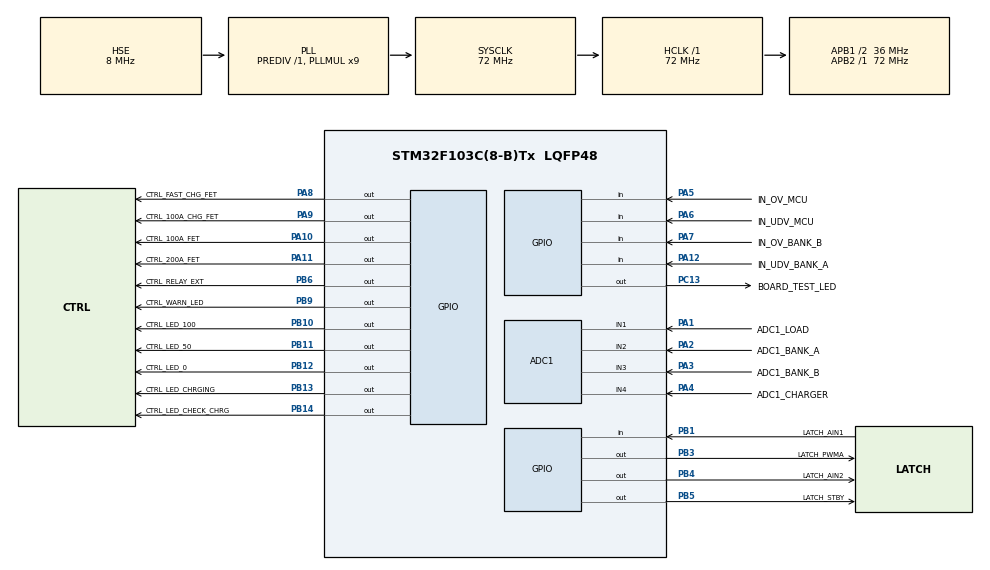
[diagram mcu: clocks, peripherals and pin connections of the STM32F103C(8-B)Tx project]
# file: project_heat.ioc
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ADC1.Channel-0\#ChannelRegularConversion=ADC_CHANNEL_1
ADC1.Channel-1\#ChannelRegularConversion=ADC_CHANNEL_2
ADC1.Channel-2\#ChannelRegularConversion=ADC_CHANNEL_3
ADC1.Channel-3\#ChannelRegularConversion=ADC_CHANNEL_4
ADC1.NbrOfConversion=4
ADC1.NbrOfConversionFlag=1
ADC1.Rank-0\#ChannelRegularConversion=1
ADC1.Rank-1\#ChannelRegularConversion=2
ADC1.Rank-2\#ChannelRegularConversion=3
ADC1.Rank-3\#ChannelRegularConversion=4
ADC1.SamplingTime-0\#ChannelRegularConversion=ADC_SAMPLETIME_239CYCLES_5
ADC1.SamplingTime-1\#ChannelRegularConversion=ADC_SAMPLETIME_239CYCLES_5
ADC1.SamplingTime-2\#ChannelRegularConversion=ADC_SAMPLETIME_1CYCLE_5
ADC1.SamplingTime-3\#ChannelRegularConversion=ADC_SAMPLETIME_239CYCLES_5
ADC1.master=1
Dma.ADC1.0.Direction=DMA_PERIPH_TO_MEMORY
Dma.ADC1.0.Instance=DMA1_Channel1
Dma.ADC1.0.MemDataAlignment=DMA_MDATAALIGN_HALFWORD
Dma.ADC1.0.MemInc=DMA_MINC_ENABLE
Dma.ADC1.0.Mode=DMA_CIRCULAR
Dma.ADC1.0.PeriphDataAlignment=DMA_PDATAALIGN_HALFWORD
Dma.ADC1.0.PeriphInc=DMA_PINC_DISABLE
Dma.ADC1.0.Priority=DMA_PRIORITY_LOW
Dma.Request0=ADC1
Mcu.Family=STM32F1
Mcu.Name=STM32F103C(8-B)Tx
Mcu.Package=LQFP48
NVIC.DMA1_Channel1_IRQn=true\:0\:0\:false\:false\:true\:false\:true\:true
NVIC.PriorityGroup=NVIC_PRIORITYGROUP_4
PA1.GPIO_Label=ADC1_LOAD
PA1.Signal=ADCx_IN1
PA10.GPIO_Label=CTRL_100A_FET
PA10.Signal=GPIO_Output
PA11.GPIO_Label=CTRL_200A_FET
PA11.Signal=GPIO_Output
PA12.GPIO_Label=IN_UDV_BANK_A
PA12.Signal=GPIO_Input
PA13.Mode=Serial_Wire
PA13.Signal=SYS_JTMS-SWDIO
PA14.Mode=Serial_Wire
PA14.Signal=SYS_JTCK-SWCLK
PA2.GPIO_Label=ADC1_BANK_A
PA2.Signal=ADCx_IN2
PA3.GPIO_Label=ADC1_BANK_B
PA3.Signal=ADCx_IN3
PA4.GPIO_Label=ADC1_CHARGER
PA4.Signal=ADCx_IN4
PA5.GPIO_Label=IN_OV_MCU
PA5.Signal=GPIO_Input
PA6.GPIO_Label=IN_UDV_MCU
PA6.Signal=GPIO_Input
PA7.GPIO_Label=IN_OV_BANK_B
PA7.Signal=GPIO_Input
PA8.GPIO_Label=CTRL_FAST_CHG_FET
PA8.Signal=GPIO_Output
PA9.GPIO_Label=CTRL_100A_CHG_FET
PA9.Signal=GPIO_Output
PB1.GPIO_Label=LATCH_AIN1
PB1.Signal=GPIO_Input
PB10.GPIO_Label=CTRL_LED_100
PB10.Signal=GPIO_Output
PB11.GPIO_Label=CTRL_LED_50
PB11.Signal=GPIO_Output
PB12.GPIO_Label=CTRL_LED_0
PB12.Signal=GPIO_Output
PB13.GPIO_Label=CTRL_LED_CHRGING
PB13.Signal=GPIO_Output
PB14.GPIO_Label=CTRL_LED_CHECK_CHRG
PB14.Signal=GPIO_Output
PB3.GPIO_Label=LATCH_PWMA
PB3.Signal=GPIO_Output
PB4.GPIO_Label=LATCH_AIN2
PB4.Signal=GPIO_Output
PB5.GPIO_Label=LATCH_STBY
PB5.Signal=GPIO_Output
PB6.GPIO_Label=CTRL_RELAY_EXT
PB6.Signal=GPIO_Output
PB9.GPIO_Label=CTRL_WARN_LED
PB9.Signal=GPIO_Output
PC13-TAMPER-RTC.GPIO_Label=BOARD_TEST_LED
PC13-TAMPER-RTC.Signal=GPIO_Output
PD0-OSC_IN.Mode=HSE-External-Oscillator
PD0-OSC_IN.Signal=RCC_OSC_IN
PD1-OSC_OUT.Mode=HSE-External-Oscillator
PD1-OSC_OUT.Signal=RCC_OSC_OUT
ProjectManager.HeapSize=0x200
ProjectManager.StackSize=0x400
ProjectManager.TargetToolchain=STM32CubeIDE
RCC.ADCPresc=RCC_ADCPCLK2_DIV6
RCC.AHBFreq_Value=72000000
RCC.APB1CLKDivider=RCC_HCLK_DIV2
RCC.APB1Freq_Value=36000000
RCC.APB1TimFreq_Value=72000000
RCC.APB2Freq_Value=72000000
RCC.APB2TimFreq_Value=72000000
RCC.HCLKFreq_Value=72000000
RCC.PLLMUL=RCC_PLL_MUL9
RCC.PLLSourceVirtual=RCC_PLLSOURCE_HSE
RCC.SYSCLKFreq_VALUE=72000000
RCC.SYSCLKSource=RCC_SYSCLKSOURCE_PLLCLK
RCC.USBFreq_Value=72000000
SH.ADCx_IN1.0=ADC1_IN1,IN1
SH.ADCx_IN2.0=ADC1_IN2,IN2
SH.ADCx_IN3.0=ADC1_IN3,IN3
SH.ADCx_IN4.0=ADC1_IN4,IN4
TIM2.AutoReloadPreload=TIM_AUTORELOAD_PRELOAD_ENABLE
TIM2.Period=99
TIM2.Prescaler=71
VP_TIM2_VS_ClockSourceINT.Mode=Internal
board=custom

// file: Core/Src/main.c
/* USER CODE BEGIN Header */
/**
  ******************************************************************************
  * @file           : main.c
  * @brief          : Main program body
  ******************************************************************************
  * @attention
  *
  * Copyright (c) 2024 STMicroelectronics.
  * All rights reserved.
  *
  * This software is licensed under terms that can be found in the LICENSE file
  * in the root directory of this software component.
  * If no LICENSE file comes with this software, it is provided AS-IS.
  *
  ******************************************************************************
  */
/* USER CODE END Header */
#include "main.h"

/* USER CODE BEGIN Includes */
#include "main_app.h"
/* USER CODE END Includes */

ADC_HandleTypeDef hadc1;
DMA_HandleTypeDef hdma_adc1;

TIM_HandleTypeDef htim2;

void SystemClock_Config(void);
static void MX_GPIO_Init(void);
static void MX_DMA_Init(void);
static void MX_ADC1_Init(void);
static void MX_TIM2_Init(void);

int main(void)
{

  /* MCU Configuration--------------------------------------------------------*/

  /* Reset of all peripherals, Initializes the Flash interface and the Systick. */
  HAL_Init();

  /* Configure the system clock */
  SystemClock_Config();

  /* Initialize all configured peripherals */
  MX_GPIO_Init();
  MX_DMA_Init();
  MX_ADC1_Init();
  MX_TIM2_Init();

  /* Infinite loop */
  while (1)
  {

    /* USER CODE BEGIN 3 */
	  main_app();
  }
  /* USER CODE END 3 */
}

void SystemClock_Config(void)
{
  RCC_OscInitTypeDef RCC_OscInitStruct = {0};
  RCC_ClkInitTypeDef RCC_ClkInitStruct = {0};
  RCC_PeriphCLKInitTypeDef PeriphClkInit = {0};

  /** Initializes the RCC Oscillators according to the specified parameters
  * in the RCC_OscInitTypeDef structure.
  */
  RCC_OscInitStruct.OscillatorType = RCC_OSCILLATORTYPE_HSE;
  RCC_OscInitStruct.HSEState = RCC_HSE_ON;
  RCC_OscInitStruct.HSEPredivValue = RCC_HSE_PREDIV_DIV1;
  RCC_OscInitStruct.HSIState = RCC_HSI_ON;
  RCC_OscInitStruct.PLL.PLLState = RCC_PLL_ON;
  RCC_OscInitStruct.PLL.PLLSource = RCC_PLLSOURCE_HSE;
  RCC_OscInitStruct.PLL.PLLMUL = RCC_PLL_MUL9;
  if (HAL_RCC_OscConfig(&RCC_OscInitStruct) != HAL_OK)
  {
    Error_Handler();
  }

  /** Initializes the CPU, AHB and APB buses clocks
  */
  RCC_ClkInitStruct.ClockType = RCC_CLOCKTYPE_HCLK|RCC_CLOCKTYPE_SYSCLK
                              |RCC_CLOCKTYPE_PCLK1|RCC_CLOCKTYPE_PCLK2;
  RCC_ClkInitStruct.SYSCLKSource = RCC_SYSCLKSOURCE_PLLCLK;
  RCC_ClkInitStruct.AHBCLKDivider = RCC_SYSCLK_DIV1;
  RCC_ClkInitStruct.APB1CLKDivider = RCC_HCLK_DIV2;
  RCC_ClkInitStruct.APB2CLKDivider = RCC_HCLK_DIV1;

  if (HAL_RCC_ClockConfig(&RCC_ClkInitStruct, FLASH_LATENCY_2) != HAL_OK)
  {
    Error_Handler();
  }
  PeriphClkInit.PeriphClockSelection = RCC_PERIPHCLK_ADC;
  PeriphClkInit.AdcClockSelection = RCC_ADCPCLK2_DIV6;
  if (HAL_RCCEx_PeriphCLKConfig(&PeriphClkInit) != HAL_OK)
  {
    Error_Handler();
  }
}

static void MX_ADC1_Init(void)
{

  ADC_ChannelConfTypeDef sConfig = {0};

  /** Common config
  */
  hadc1.Instance = ADC1;
  hadc1.Init.ScanConvMode = ADC_SCAN_ENABLE;
  hadc1.Init.ContinuousConvMode = DISABLE;
  hadc1.Init.DiscontinuousConvMode = DISABLE;
  hadc1.Init.ExternalTrigConv = ADC_SOFTWARE_START;
  hadc1.Init.DataAlign = ADC_DATAALIGN_RIGHT;
  hadc1.Init.NbrOfConversion = 4;
  if (HAL_ADC_Init(&hadc1) != HAL_OK)
  {
    Error_Handler();
  }

  /** Configure Regular Channel
  */
  sConfig.Channel = ADC_CHANNEL_1;
  sConfig.Rank = ADC_REGULAR_RANK_1;
  sConfig.SamplingTime = ADC_SAMPLETIME_239CYCLES_5;
  if (HAL_ADC_ConfigChannel(&hadc1, &sConfig) != HAL_OK)
  {
    Error_Handler();
  }

  /** Configure Regular Channel
  */
  sConfig.Channel = ADC_CHANNEL_2;
  sConfig.Rank = ADC_REGULAR_RANK_2;
  if (HAL_ADC_ConfigChannel(&hadc1, &sConfig) != HAL_OK)
  {
    Error_Handler();
  }

  /** Configure Regular Channel
  */
  sConfig.Channel = ADC_CHANNEL_3;
  sConfig.Rank = ADC_REGULAR_RANK_3;
  sConfig.SamplingTime = ADC_SAMPLETIME_1CYCLE_5;
  if (HAL_ADC_ConfigChannel(&hadc1, &sConfig) != HAL_OK)
  {
    Error_Handler();
  }

  /** Configure Regular Channel
  */
  sConfig.Channel = ADC_CHANNEL_4;
  sConfig.Rank = ADC_REGULAR_RANK_4;
  sConfig.SamplingTime = ADC_SAMPLETIME_239CYCLES_5;
  if (HAL_ADC_ConfigChannel(&hadc1, &sConfig) != HAL_OK)
  {
    Error_Handler();
  }

}

static void MX_TIM2_Init(void)
{

  TIM_ClockConfigTypeDef sClockSourceConfig = {0};
  TIM_MasterConfigTypeDef sMasterConfig = {0};

  htim2.Instance = TIM2;
  htim2.Init.Prescaler = 71;
  htim2.Init.CounterMode = TIM_COUNTERMODE_UP;
  htim2.Init.Period = 99;
  htim2.Init.ClockDivision = TIM_CLOCKDIVISION_DIV1;
  htim2.Init.AutoReloadPreload = TIM_AUTORELOAD_PRELOAD_ENABLE;
  if (HAL_TIM_Base_Init(&htim2) != HAL_OK)
  {
    Error_Handler();
  }
  sClockSourceConfig.ClockSource = TIM_CLOCKSOURCE_INTERNAL;
  if (HAL_TIM_ConfigClockSource(&htim2, &sClockSourceConfig) != HAL_OK)
  {
    Error_Handler();
  }
  sMasterConfig.MasterOutputTrigger = TIM_TRGO_RESET;
  sMasterConfig.MasterSlaveMode = TIM_MASTERSLAVEMODE_DISABLE;
  if (HAL_TIMEx_MasterConfigSynchronization(&htim2, &sMasterConfig) != HAL_OK)
  {
    Error_Handler();
  }

}

static void MX_DMA_Init(void)
{

  /* DMA controller clock enable */
  __HAL_RCC_DMA1_CLK_ENABLE();

  /* DMA interrupt init */
  /* DMA1_Channel1_IRQn interrupt configuration */
  HAL_NVIC_SetPriority(DMA1_Channel1_IRQn, 0, 0);
  HAL_NVIC_EnableIRQ(DMA1_Channel1_IRQn);

}

static void MX_GPIO_Init(void)
{
  GPIO_InitTypeDef GPIO_InitStruct = {0};

  /* GPIO Ports Clock Enable */
  __HAL_RCC_GPIOC_CLK_ENABLE();
  __HAL_RCC_GPIOD_CLK_ENABLE();
  __HAL_RCC_GPIOA_CLK_ENABLE();
  __HAL_RCC_GPIOB_CLK_ENABLE();

  /*Configure GPIO pin Output Level */
  HAL_GPIO_WritePin(BOARD_TEST_LED_GPIO_Port, BOARD_TEST_LED_Pin, GPIO_PIN_RESET);

  /*Configure GPIO pin Output Level */
  HAL_GPIO_WritePin(GPIOB, CTRL_LED_100_Pin|CTRL_LED_50_Pin|CTRL_LED_0_Pin|CTRL_LED_CHRGING_Pin
                          |CTRL_LED_CHECK_CHRG_Pin|LATCH_PWMA_Pin|LATCH_AIN2_Pin|LATCH_STBY_Pin
                          |CTRL_RELAY_EXT_Pin|CTRL_WARN_LED_Pin, GPIO_PIN_RESET);

  /*Configure GPIO pin Output Level */
  HAL_GPIO_WritePin(GPIOA, CTRL_FAST_CHG_FET_Pin|CTRL_100A_CHG_FET_Pin|CTRL_100A_FET_Pin|CTRL_200A_FET_Pin, GPIO_PIN_RESET);

  /*Configure GPIO pin : BOARD_TEST_LED_Pin */
  GPIO_InitStruct.Pin = BOARD_TEST_LED_Pin;
  GPIO_InitStruct.Mode = GPIO_MODE_OUTPUT_PP;
  GPIO_InitStruct.Pull = GPIO_NOPULL;
  GPIO_InitStruct.Speed = GPIO_SPEED_FREQ_LOW;
  HAL_GPIO_Init(BOARD_TEST_LED_GPIO_Port, &GPIO_InitStruct);

  /*Configure GPIO pins : IN_OV_MCU_Pin IN_UDV_MCU_Pin IN_OV_BANK_B_Pin IN_UDV_BANK_A_Pin */
  GPIO_InitStruct.Pin = IN_OV_MCU_Pin|IN_UDV_MCU_Pin|IN_OV_BANK_B_Pin|IN_UDV_BANK_A_Pin;
  GPIO_InitStruct.Mode = GPIO_MODE_INPUT;
  GPIO_InitStruct.Pull = GPIO_NOPULL;
  HAL_GPIO_Init(GPIOA, &GPIO_InitStruct);

  /*Configure GPIO pin : LATCH_AIN1_Pin */
  GPIO_InitStruct.Pin = LATCH_AIN1_Pin;
  GPIO_InitStruct.Mode = GPIO_MODE_INPUT;
  GPIO_InitStruct.Pull = GPIO_NOPULL;
  HAL_GPIO_Init(LATCH_AIN1_GPIO_Port, &GPIO_InitStruct);

  /*Configure GPIO pins : CTRL_LED_100_Pin CTRL_LED_50_Pin CTRL_LED_0_Pin CTRL_LED_CHRGING_Pin
                           CTRL_LED_CHECK_CHRG_Pin LATCH_PWMA_Pin LATCH_AIN2_Pin LATCH_STBY_Pin
                           CTRL_RELAY_EXT_Pin CTRL_WARN_LED_Pin */
  GPIO_InitStruct.Pin = CTRL_LED_100_Pin|CTRL_LED_50_Pin|CTRL_LED_0_Pin|CTRL_LED_CHRGING_Pin
                          |CTRL_LED_CHECK_CHRG_Pin|LATCH_PWMA_Pin|LATCH_AIN2_Pin|LATCH_STBY_Pin
                          |CTRL_RELAY_EXT_Pin|CTRL_WARN_LED_Pin;
  GPIO_InitStruct.Mode = GPIO_MODE_OUTPUT_PP;
  GPIO_InitStruct.Pull = GPIO_NOPULL;
  GPIO_InitStruct.Speed = GPIO_SPEED_FREQ_LOW;
  HAL_GPIO_Init(GPIOB, &GPIO_InitStruct);

  /*Configure GPIO pins : CTRL_FAST_CHG_FET_Pin CTRL_100A_CHG_FET_Pin CTRL_100A_FET_Pin CTRL_200A_FET_Pin */
  GPIO_InitStruct.Pin = CTRL_FAST_CHG_FET_Pin|CTRL_100A_CHG_FET_Pin|CTRL_100A_FET_Pin|CTRL_200A_FET_Pin;
  GPIO_InitStruct.Mode = GPIO_MODE_OUTPUT_PP;
  GPIO_InitStruct.Pull = GPIO_NOPULL;
  GPIO_InitStruct.Speed = GPIO_SPEED_FREQ_LOW;
  HAL_GPIO_Init(GPIOA, &GPIO_InitStruct);

}

void Error_Handler(void)
{
  __disable_irq();
  while (1)
  {
  }
}
